VERSION ""

NS_ :

BS_:

BU_: XXX

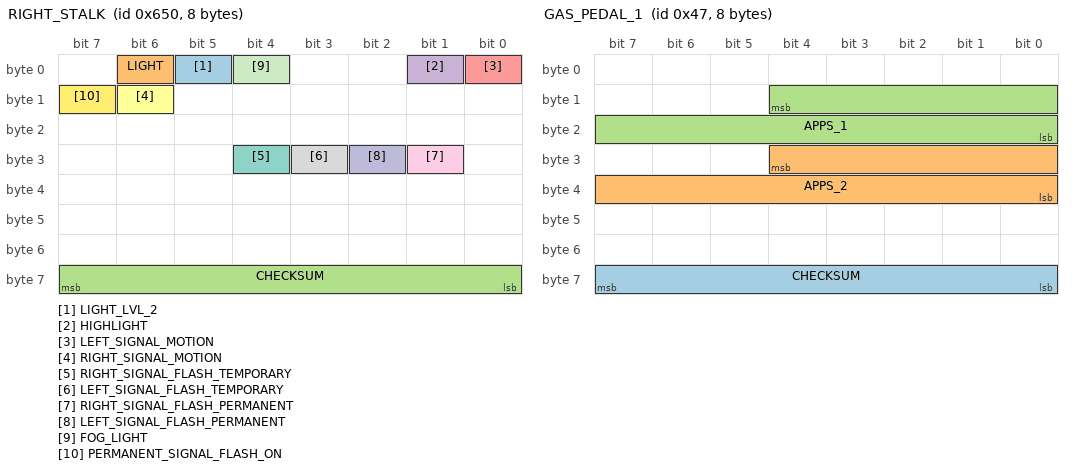
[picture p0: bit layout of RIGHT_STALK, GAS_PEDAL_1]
BO_ 1616 RIGHT_STALK: 8 XXX
 SG_ LIGHT_LVL_2 : 5|1@0+ (1,0) [0|1] "" XXX
 SG_ LIGHT : 6|1@0+ (1,0) [0|1] "" XXX
 SG_ CHECKSUM : 63|8@0+ (1,0) [0|255] "" XXX
 SG_ HIGHLIGHT : 1|1@0+ (1,0) [0|1] "" XXX
 SG_ LEFT_SIGNAL_MOTION : 0|1@0+ (1,0) [0|1] "" XXX
 SG_ RIGHT_SIGNAL_MOTION : 14|1@0+ (1,0) [0|1] "" XXX
 SG_ RIGHT_SIGNAL_FLASH_TEMPORARY : 28|1@0+ (1,0) [0|1] "" XXX
 SG_ LEFT_SIGNAL_FLASH_TEMPORARY : 27|1@0+ (1,0) [0|1] "" XXX
 SG_ RIGHT_SIGNAL_FLASH_PERMANENT : 25|1@0+ (1,0) [0|1] "" XXX
 SG_ LEFT_SIGNAL_FLASH_PERMANENT : 26|1@0+ (1,0) [0|1] "" XXX
 SG_ FOG_LIGHT : 4|1@0+ (1,0) [0|1] "" XXX
 SG_ PERMANENT_SIGNAL_FLASH_ON : 15|1@0+ (1,0) [0|1] "" XXX

BO_ 384 HANDBRAKE: 4 XXX
 SG_ HANDBRAKE_ON : 0|1@0+ (1,0) [0|1] "" XXX
 SG_ CHECKSUM : 31|8@0+ (1,0) [0|255] "" XXX

BO_ 71 GAS_PEDAL_1: 8 XXX
 SG_ CHECKSUM : 63|8@0+ (1,0) [0|255] "" XXX
 SG_ APPS_2 : 28|13@0+ (1,0) [0|8191] "" XXX
 SG_ APPS_1 : 12|13@0+ (0.00015625,0) [0|8191] "" XXX

BO_ 33 BRAKE_PEDAL: 8 XXX
 SG_ CHECKSUM : 63|8@0+ (1,0) [0|255] "" XXX
 SG_ BRAKE_ENGAGED : 5|1@0+ (1,0) [0|1] "" XXX

BO_ 1584 METER_CLUSTER: 6 XXX
 SG_ BACK_PASSENGER_LEFT : 5|1@0+ (1,0) [0|1] "" XXX
 SG_ BACK_DRIVER_RIGHT : 4|1@0+ (1,0) [0|1] "" XXX
 SG_ FRONT_PASSENGER_LEFT : 3|1@0+ (1,0) [0|1] "" XXX
 SG_ FRONT_DRIVER_RIGHT : 9|1@0+ (1,0) [0|1] "" XXX
 SG_ RIGHT_SIGNAL_FLASH : 15|1@0+ (1,0) [0|1] "" XXX
 SG_ LEFT_SIGNAL_FLASH : 14|1@0+ (1,0) [0|1] "" XXX
 SG_ FOG_LIGHT : 30|1@0+ (1,0) [0|1] "" XXX
 SG_ EVENING_LIGHT_AND_LOW_BEAM : 11|1@0+ (1,0) [0|1] "" XXX
 SG_ LOW_AND_HIGH_BEAM : 8|1@0+ (1,0) [0|1] "" XXX
 SG_ HIGH_BEAM : 31|1@0+ (1,0) [0|1] "" XXX
 SG_ CHECKSUM : 47|8@0+ (1,0) [0|255] "" XXX
 SG_ DOOR_OPEN : 1|3@1+ (1,0) [0|3] "" XXX
 SG_ DRIVER_SEATBELT : 10|1@0+ (1,0) [0|511] "" XXX

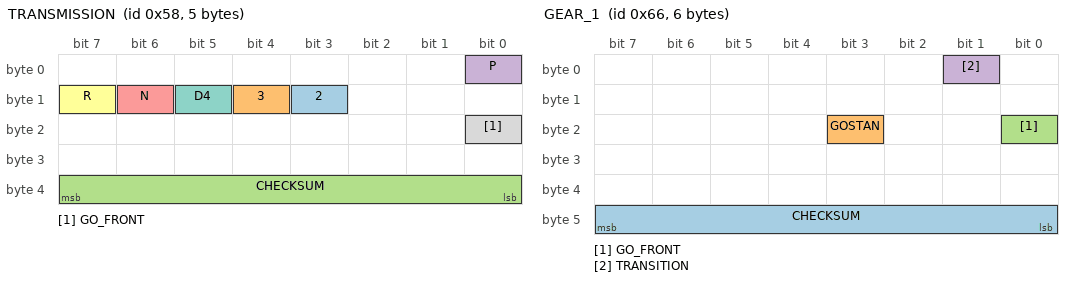
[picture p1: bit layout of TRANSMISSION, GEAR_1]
BO_ 88 TRANSMISSION: 5 XXX
 SG_ 2 : 11|1@0+ (1,0) [0|1] "" XXX
 SG_ 3 : 12|1@0+ (1,0) [0|1] "" XXX
 SG_ CHECKSUM : 39|8@0+ (1,0) [0|255] "" XXX
 SG_ P : 0|1@0+ (1,0) [0|1] "" XXX
 SG_ N : 14|1@1+ (1,0) [0|511] "" XXX
 SG_ R : 15|1@0+ (1,0) [0|1] "" XXX
 SG_ D4 : 13|1@0+ (1,0) [0|1] "" XXX
 SG_ GO_FRONT : 16|1@0+ (1,0) [0|1] "" XXX

BO_ 102 GEAR_1: 6 XXX
 SG_ CHECKSUM : 47|8@0+ (1,0) [0|255] "" XXX
 SG_ GOSTAN : 19|1@0+ (1,0) [0|1] "" XXX
 SG_ GO_FRONT : 16|1@0+ (1,0) [0|1] "" XXX
 SG_ TRANSITION : 1|1@0+ (1,0) [0|1] "" XXX

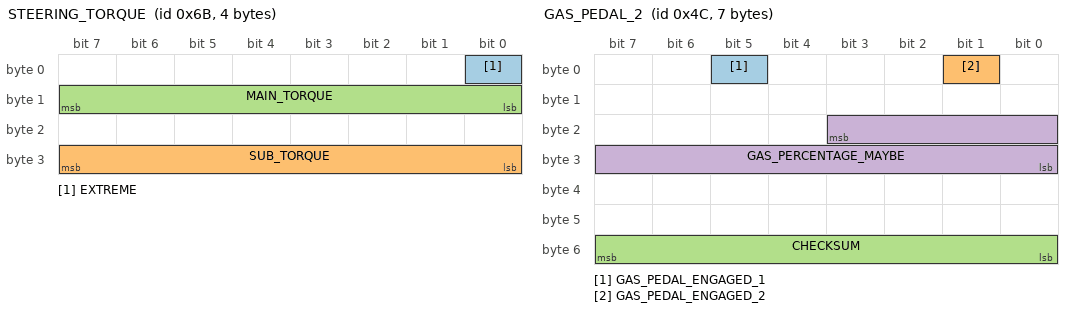
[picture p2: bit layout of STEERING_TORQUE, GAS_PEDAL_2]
BO_ 107 STEERING_TORQUE: 4 XXX
 SG_ EXTREME : 0|1@0+ (1,0) [0|1] "" XXX
 SG_ SUB_TORQUE : 31|8@0+ (1,-111) [0|256] "" XXX
 SG_ MAIN_TORQUE : 15|8@0+ (1,0) [0|255] "" XXX

BO_ 76 GAS_PEDAL_2: 7 XXX
 SG_ GAS_PEDAL_ENGAGED_1 : 5|1@0+ (1,0) [0|255] "" XXX
 SG_ GAS_PEDAL_ENGAGED_2 : 1|1@0+ (1,0) [0|1] "" XXX
 SG_ CHECKSUM : 48|8@1+ (1,0) [0|255] "" XXX
 SG_ GAS_PERCENTAGE_MAYBE : 19|12@0+ (0.00188679245283018867924528301887,6.0037735849056603773584905660377) [0|4095] "" XXX

CM_ SG_ 1584 DRIVER_SEATBELT "1 = seatbelt not latched";
